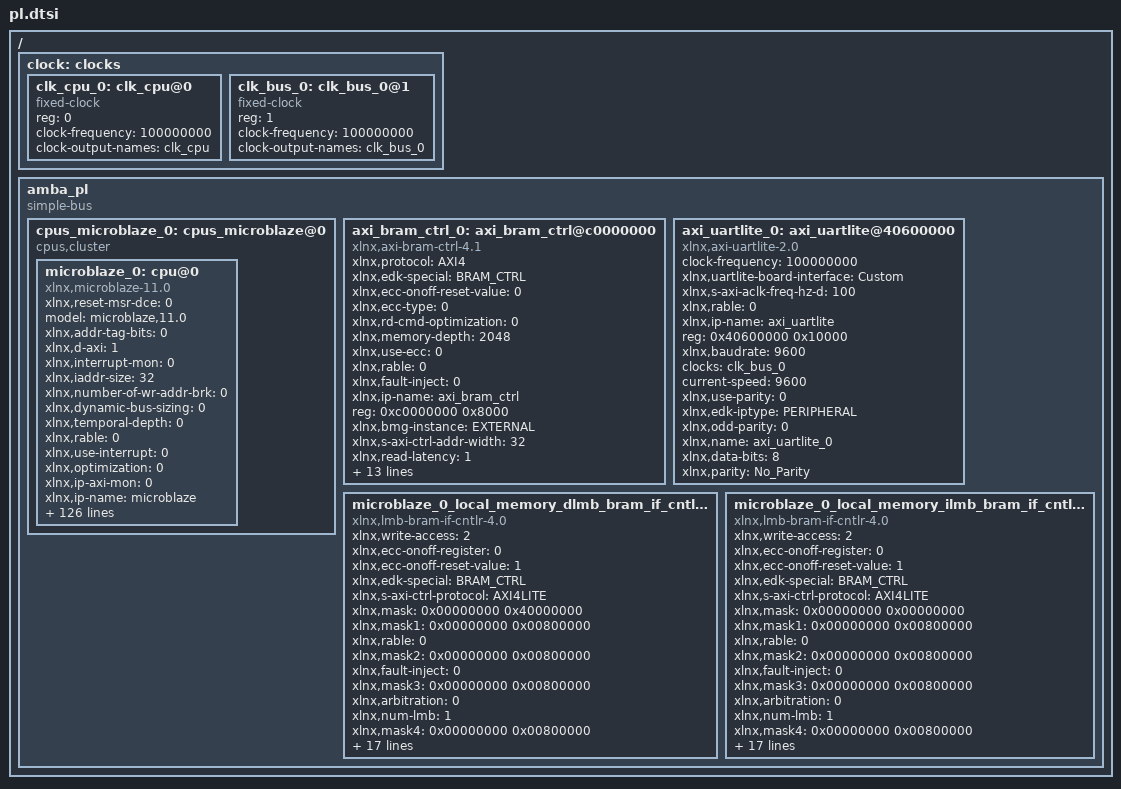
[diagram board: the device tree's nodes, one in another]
/ {
	clock: clocks {
		#address-cells = <1>;
		#size-cells = <0>;
		clk_cpu_0: clk_cpu@0 {
			compatible = "fixed-clock";
			reg = <0>;
			clock-frequency = <100000000>;
			clock-output-names = "clk_cpu";
			#clock-cells = <0>;
		};
		clk_bus_0: clk_bus_0@1 {
			compatible = "fixed-clock";
			reg = <1>;
			clock-frequency = <100000000>;
			clock-output-names = "clk_bus_0";
			#clock-cells = <0>;
		};
	};
	amba_pl: amba_pl {
		ranges;
		compatible = "simple-bus";
		#address-cells = <1>;
		#size-cells = <1>;
		cpus_microblaze_0: cpus_microblaze@0 {
			#cpu-mask-cells = <1>;
			compatible = "cpus,cluster";
			#address-cells = <1>;
			#size-cells = <0>;
			microblaze_0: cpu@0 {
				xlnx,reset-msr-dce = <0>;
				model = "microblaze,11.0";
				xlnx,addr-tag-bits = <0>;
				xlnx,d-axi = <1>;
				xlnx,interrupt-mon = <0>;
				xlnx,iaddr-size = <32>;
				xlnx,number-of-wr-addr-brk = <0>;
				xlnx,dynamic-bus-sizing = <0>;
				xlnx,temporal-depth = <0>;
				xlnx,rable = <0>;
				xlnx,use-interrupt = <0>;
				xlnx,optimization = <0>;
				xlnx,ip-axi-mon = <0>;
				xlnx,ip-name = "microblaze";
				d-cache-highaddr = <0x3fffffff>;
				xlnx,dcache-force-tag-lutram = <0>;
				xlnx,pc-width = <32>;
				xlnx,interrupt-is-edge = <0>;
				reg = <0x0>;
				xlnx,async-interrupt = <1>;
				xlnx,use-mmu = <0>;
				xlnx,reset-msr-ee = <0>;
				xlnx,icache-victims = <0>;
				xlnx,use-reorder-instr = <1>;
				xlnx,d-lmb-mon = <0>;
				xlnx,d-lmb-protocol = <0>;
				xlnx,ill-opcode-exception = <0>;
				xlnx,dcache-always-used = <1>;
				xlnx,use-div = <0>;
				xlnx,dc-axi-mon = <0>;
				xlnx,debug-trace-async-reset = <0>;
				xlnx,trace = <0>;
				xlnx,part = "xc7a35tcpg236-1";
				i-cache-baseaddr = <0x00000000>;
				xlnx,use-config-reset = <0>;
				xlnx,pvr = <0>;
				xlnx,i-lmb-mon = <0>;
				xlnx,dcache-byte-size = <8192>;
				xlnx,fault-tolerant = <0>;
				xlnx,family = "artix7";
				compatible = "xlnx,microblaze-11.0" , "xlnx,microblaze";
				xlnx,data-size = <32>;
				xlnx,mmu-zones = <16>;
				xlnx,debug-trace-size = <8192>;
				xlnx,mmu-privileged-instr = <0>;
				xlnx,enable-discrete-ports = <0>;
				d-cache-line-size = <16>;
				xlnx,d-lmb = <1>;
				xlnx,sco = <0>;
				xlnx,reset-msr-eip = <0>;
				clock-frequency = <100000000>;
				xlnx,debug-interface = <0>;
				xlnx,use-ext-brk = <0>;
				xlnx,daddr-size = <32>;
				xlnx,debug-enabled = <1>;
				xlnx,reset-msr-ice = <0>;
				xlnx,num-sync-ff-dbg-trace-clk = <2>;
				xlnx,i-lmb-protocol = <0>;
				xlnx,endianness = <1>;
				xlnx,fsl-exception = <0>;
				i-cache-line-size = <16>;
				xlnx,use-extended-fsl-instr = <0>;
				xlnx,reset-msr = <0x00000000>;
				xlnx,dp-axi-mon = <0>;
				xlnx,branch-target-cache-size = <0>;
				xlnx,dcache-use-writeback = <0>;
				xlnx,div-zero-exception = <0>;
				xlnx,mmu-tlb-access = <3>;
				bus-handle = <&amba_pl>;
				xlnx,cache-byte-size = <8192>;
				xlnx,pvr-user2 = <0x00000000>;
				xlnx,opcode-0x0-illegal = <0>;
				xlnx,icache-line-len = <4>;
				xlnx,ecc-use-ce-exception = <0>;
				xlnx,base-vectors = <0x00000000 0x00000000>;
				xlnx,use-dcache = <0>;
				xlnx,use-barrel = <0>;
				xlnx,reset-msr-bip = <0>;
				xlnx,edk-special = "microblaze";
				xlnx,allow-dcache-wr = <1>;
				xlnx,addr-size = <32>;
				xlnx,debug-external-trace = <0>;
				xlnx,piaddr-size = <32>;
				i-cache-highaddr = <0x3fffffff>;
				xlnx,num-sync-ff-clk-debug = <2>;
				xlnx,debug-event-counters = <5>;
				xlnx,fpu-exception = <0>;
				xlnx,allow-icache-wr = <1>;
				xlnx,i-axi = <0>;
				xlnx,g-use-exceptions = <0>;
				xlnx,icache-streams = <0>;
				xlnx,g-template-list = <0>;
				xlnx,dcache-line-len = <4>;
				xlnx,num-sync-ff-clk = <2>;
				xlnx,use-stack-protection = <0>;
				xlnx,use-hw-mul = <0>;
				xlnx,num-sync-ff-dbg-clk = <1>;
				xlnx,interconnect = <2>;
				xlnx,edk-iptype = "PROCESSOR";
				i-cache-size = <8192>;
				xlnx,debug-latency-counters = <1>;
				xlnx,use-fpu = <0>;
				xlnx,reset-msr-ie = <0>;
				xlnx,edge-is-positive = <1>;
				xlnx,use-pcmp-instr = <0>;
				xlnx,use-icache = <0>;
				d-cache-size = <8192>;
				xlnx,async-wakeup = <3>;
				xlnx,use-non-secure = <0>;
				xlnx,dcache-addr-tag = <0>;
				xlnx,number-of-rd-addr-brk = <0>;
				d-cache-baseaddr = <0x00000000>;
				xlnx,area-optimized = <0>;
				xlnx,avoid-primitives = <0>;
				xlnx,lockstep-slave = <0>;
				xlnx,use-ext-nm-brk = <0>;
				xlnx,instr-size = <32>;
				xlnx,icache-always-used = <1>;
				xlnx,i-lmb = <1>;
				xlnx,mmu-dtlb-size = <4>;
				xlnx,lockstep-select = <0>;
				xlnx,lmb-data-size = <32>;
				xlnx,ic-axi-mon = <0>;
				xlnx,enable-conversion = <1>;
				xlnx,num-sync-ff-clk-irq = <1>;
				xlnx,fsl-links = <0>;
				timebase-frequency = <100000000>;
				xlnx,icache-force-tag-lutram = <0>;
				xlnx,dcache-data-width = <0>;
				xlnx,dcache-victims = <0>;
				xlnx,use-branch-target-cache = <0>;
				xlnx,debug-profile-size = <0>;
				xlnx,unaligned-exceptions = <0>;
				xlnx,lockstep-master = <0>;
				xlnx,freq = <100000000>;
				xlnx,number-of-pc-brk = <1>;
				xlnx,mmu-itlb-size = <2>;
				xlnx,imprecise-exceptions = <0>;
				xlnx,use-msr-instr = <0>;
				xlnx,icache-data-width = <0>;
				xlnx,debug-counter-width = <32>;
			};
		};
		axi_bram_ctrl_0: axi_bram_ctrl@c0000000 {
			xlnx,protocol = "AXI4";
			xlnx,edk-special = "BRAM_CTRL";
			compatible = "xlnx,axi-bram-ctrl-4.1";
			xlnx,ecc-onoff-reset-value = <0>;
			xlnx,ecc-type = <0>;
			xlnx,rd-cmd-optimization = <0>;
			xlnx,memory-depth = <2048>;
			xlnx,use-ecc = <0>;
			xlnx,rable = <0>;
			xlnx,fault-inject = <0>;
			xlnx,ip-name = "axi_bram_ctrl";
			reg = <0xc0000000 0x8000>;
			xlnx,bmg-instance = "EXTERNAL";
			xlnx,s-axi-ctrl-addr-width = <32>;
			xlnx,read-latency = <1>;
			xlnx,s-axi-supports-narrow-burst = <0>;
			xlnx,id-width = <0>;
			xlnx,supports-narrow-burst = <0>;
			xlnx,single-port-bram = <1>;
			xlnx,ecc = <0>;
			xlnx,edk-iptype = "PERIPHERAL";
			status = "okay";
			xlnx,bram-addr-width = <11>;
			xlnx,bram-inst-mode = "EXTERNAL";
			xlnx,data-width = <128>;
			xlnx,s-axi-ctrl-data-width = <32>;
			xlnx,s-axi-id-width = <1>;
			xlnx,mem-depth = <2048>;
			xlnx,name = "axi_bram_ctrl_0";
		};
		axi_uartlite_0: axi_uartlite@40600000 {
			compatible = "xlnx,axi-uartlite-2.0" , "xlnx,xps-uartlite-1.00.a";
			clock-frequency = <100000000>;
			xlnx,uartlite-board-interface = "Custom";
			xlnx,s-axi-aclk-freq-hz-d = <100>;
			xlnx,rable = <0>;
			xlnx,ip-name = "axi_uartlite";
			reg = <0x40600000 0x10000>;
			xlnx,baudrate = <9600>;
			clocks = <&clk_bus_0>;
			current-speed = <9600>;
			xlnx,use-parity = <0>;
			xlnx,edk-iptype = "PERIPHERAL";
			xlnx,odd-parity = <0>;
			status = "okay";
			xlnx,name = "axi_uartlite_0";
			xlnx,data-bits = <8>;
			xlnx,parity = "No_Parity";
		};
		microblaze_0_local_memory_dlmb_bram_if_cntlr: lmb_bram_if_cntlr@0 {
			xlnx,write-access = <2>;
			compatible = "xlnx,lmb-bram-if-cntlr-4.0";
			xlnx,ecc-onoff-register = <0>;
			xlnx,ecc-onoff-reset-value = <1>;
			xlnx,edk-special = "BRAM_CTRL";
			xlnx,s-axi-ctrl-protocol = "AXI4LITE";
			xlnx,mask = <0x00000000 0x40000000>;
			xlnx,mask1 = <0x00000000 0x00800000>;
			xlnx,rable = <0>;
			xlnx,mask2 = <0x00000000 0x00800000>;
			xlnx,fault-inject = <0>;
			xlnx,mask3 = <0x00000000 0x00800000>;
			xlnx,arbitration = <0>;
			xlnx,num-lmb = <1>;
			xlnx,mask4 = <0x00000000 0x00800000>;
			reg = <0x00000000 0x10000>;
			xlnx,s-axi-ctrl-addr-width = <32>;
			xlnx,mask5 = <0x00000000 0x00800000>;
			xlnx,ecc-status-registers = <0>;
			xlnx,mask6 = <0x00000000 0x00800000>;
			xlnx,lmb-protocol = <0>;
			xlnx,ce-counter-width = <0>;
			xlnx,mask7 = <0x00000000 0x00800000>;
			xlnx,ecc = <0>;
			xlnx,lmb-dwidth = <32>;
			xlnx,interconnect = <0>;
			xlnx,ce-failing-registers = <0>;
			xlnx,edk-iptype = "PERIPHERAL";
			xlnx,ue-failing-registers = <0>;
			xlnx,s-axi-ctrl-data-width = <32>;
			xlnx,bram-awidth = <32>;
			xlnx,lmb-awidth = <32>;
		};
		microblaze_0_local_memory_ilmb_bram_if_cntlr: lmb_bram_if_cntlr@1 {
			xlnx,write-access = <2>;
			compatible = "xlnx,lmb-bram-if-cntlr-4.0";
			xlnx,ecc-onoff-register = <0>;
			xlnx,ecc-onoff-reset-value = <1>;
			xlnx,edk-special = "BRAM_CTRL";
			xlnx,s-axi-ctrl-protocol = "AXI4LITE";
			xlnx,mask = <0x00000000 0x00000000>;
			xlnx,mask1 = <0x00000000 0x00800000>;
			xlnx,rable = <0>;
			xlnx,mask2 = <0x00000000 0x00800000>;
			xlnx,fault-inject = <0>;
			xlnx,mask3 = <0x00000000 0x00800000>;
			xlnx,arbitration = <0>;
			xlnx,num-lmb = <1>;
			xlnx,mask4 = <0x00000000 0x00800000>;
			reg = <0x00000000 0x10000>;
			xlnx,s-axi-ctrl-addr-width = <32>;
			xlnx,mask5 = <0x00000000 0x00800000>;
			xlnx,ecc-status-registers = <0>;
			xlnx,mask6 = <0x00000000 0x00800000>;
			xlnx,lmb-protocol = <0>;
			xlnx,ce-counter-width = <0>;
			xlnx,mask7 = <0x00000000 0x00800000>;
			xlnx,ecc = <0>;
			xlnx,lmb-dwidth = <32>;
			xlnx,interconnect = <0>;
			xlnx,ce-failing-registers = <0>;
			xlnx,edk-iptype = "PERIPHERAL";
			xlnx,ue-failing-registers = <0>;
			xlnx,s-axi-ctrl-data-width = <32>;
			xlnx,bram-awidth = <32>;
			xlnx,lmb-awidth = <32>;
		};
	};
};
